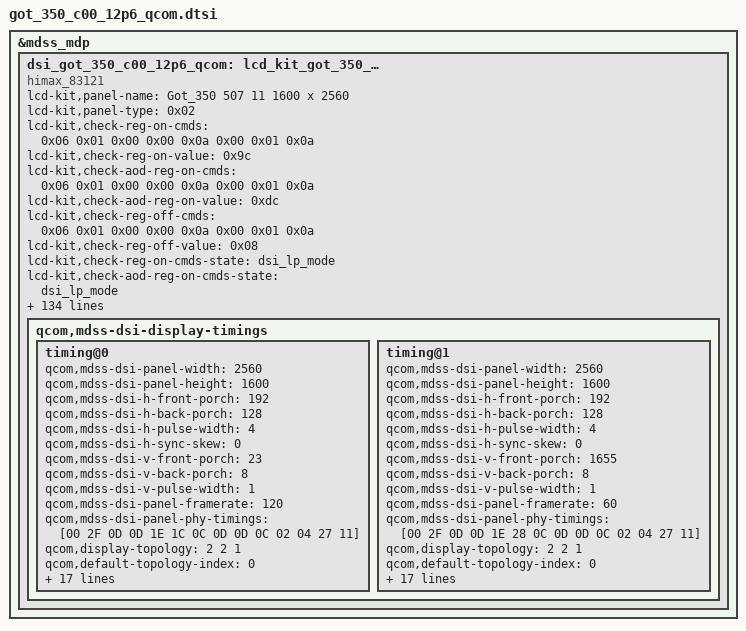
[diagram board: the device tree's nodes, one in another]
/* Copyright (c) 2013, The Linux Foundation. All rights reserved.
 *
 * This program is free software; you can redistribute it and/or modify
 * it under the terms of the GNU General Public License version 2 and
 * only version 2 as published by the Free Software Foundation.
 *
 * This program is distributed in the hope that it will be useful,
 * but WITHOUT ANY WARRANTY; without even the implied warranty of
 * MERCHANTABILITY or FITNESS FOR A PARTICULAR PURPOSE.  See the
 * GNU General Public License for more details.
 */

/*-------------------------------------------------------------------------
 * This file is autogenerated file using gcdb parser. Please do not edit it.
 * Update input XML file to add a new entry or update variable in this file
 * VERSION = 1.1
 *-----------------------------------------------------------------------*/
&mdss_mdp {
	dsi_got_350_c00_12p6_qcom: lcd_kit_got_350_c00_12p6_qcom {
		compatible = "himax_83121";
		lcd-kit,panel-name = "Got_350 507 11 1600 x 2560";
		lcd-kit,panel-type = <0x02>;
		lcd-kit,check-reg-on-cmds = <0x06 0x01 0x00 0x00 0x0a 0x00 0x01 0x0a>;
		lcd-kit,check-reg-on-value = <0x9c>;
		lcd-kit,check-aod-reg-on-cmds = <0x06 0x01 0x00 0x00 0x0a 0x00 0x01 0x0a>;
		lcd-kit,check-aod-reg-on-value = <0xdc>;
		lcd-kit,check-reg-off-cmds = <0x06 0x01 0x00 0x00 0x0a 0x00 0x01 0x0a>;
		lcd-kit,check-reg-off-value = <0x08>;
		lcd-kit,check-reg-on-cmds-state = "dsi_lp_mode";
		lcd-kit,check-aod-reg-on-cmds-state = "dsi_lp_mode";
		lcd-kit,check-reg-off-cmds-state = "dsi_lp_mode";
		lcd-kit,poweric-detect-support = <0>;
		lcd-kit,bl-after-frame = <0>;
		lcd-kit,cmd-async-support = <0>;
		lcd-kit,left-time-to-te-us = <25667>;
		lcd-kit,right-time-to-te-us = <26167>;
		lcd-kit,te-interval-time-us = <16667>;
		lcd-kit,check-reg-on-support = <0>;
		lcd-kit,check-reg-on-support-dsm-report = <0>;
		lcd-kit,check-aod-reg-on-support = <0>;
		lcd-kit,check-aod-reg-on-support-dsm-report = <0>;
		lcd-kit,check-reg-off-support = <0>;
		lcd-kit,check-reg-off-support-dsm-report = <0>;
		lcd-kit,vtc-line-no-reset = <1>;
		qcom,mdss-dsi-panel-type = "dsi_cmd_mode";
		qcom,mdss-dsi-panel-name = "himax_83121";
		qcom,mdss-pan-physical-width-dimension = <237>;
		qcom,mdss-pan-physical-height-dimension = <148>;
		qcom,dsi-ctrl-num = <0>;
		qcom,dsi-phy-num = <0>;
		qcom,panel-supply-entries = <&dsi_panel_pwr_supply>;
		qcom,mdss-dsi-virtual-channel-id = <0>;
		qcom,mdss-dsi-h-sync-pulse = <0>;
		qcom,mdss-dsi-bllp-eof-power-mode;
		qcom,mdss-dsi-bllp-power-mode;
		qcom,mdss-dsi-dma-schedule-line = <1>;
		qcom,mdss-dsi-bpp = <24>;
		qcom,mdss-dsi-color-order = "rgb_swap_rgb";
		qcom,mdss-dsi-underflow-color = <0xff>;
		qcom,mdss-dsi-border-color = <0>;
		qcom,mdss-dsi-traffic-mode = "burst_mode";
		qcom,mdss-dsi-lane-map = "lane_map_0123";
		qcom,mdss-dsi-lane-0-state;
		qcom,mdss-dsi-lane-1-state;
		qcom,mdss-dsi-lane-2-state;
		qcom,mdss-dsi-lane-3-state;
		qcom,mdss-dsi-mdp-trigger = "none";
		qcom,mdss-dsi-dma-trigger = "trigger_sw";
		qcom,mdss-dsi-te-pin-select = <1>;
		qcom,mdss-dsi-wr-mem-start = <0x2c>;
		qcom,mdss-dsi-wr-mem-continue = <0x3c>;
		qcom,mdss-dsi-te-dcs-command = <1>;
		qcom,mdss-dsi-te-check-enable;
		qcom,mdss-dsi-te-using-te-pin;
		qcom,mdss-dsi-t-clk-post = <0>;
		qcom,mdss-dsi-t-clk-pre = <0>;
		qcom,dsi-select-clocks = "mux_byte_clk0", "mux_pixel_clk0";
		qcom,mdss-dsi-stream = <0>;
		lcd-kit,check-thread-support = <0>;
		lcd-kit,check-time-period = <5000>;
		lcd-kit,check-fold-support = <0>;
		lcd-kit,fold-low-power-support = <0>;
		lcd-kit,fold-height = <0>;
		lcd-kit,unfold-height = <0>;
		lcd-kit,power-support = <0>;
		lcd-kit,three-stage-poweron = <0>;
		qcom,apaod-lp2-need-sendcmd;
		lcd-kit,fold-lp-time = <0>;
		lcd-kit,fold-nolp-time = <0>;
		qcom,sublinks-count = <2>;
		qcom,lanes-per-sublink = <2>;
		qcom,mdss-dsi-panel-hdr-color-primaries = <14500 15500 32000 17000 15500 30000 8000 3000>;
		qcom,mdss-dsi-panel-peak-brightness = <4200000>;
		qcom,mdss-dsi-panel-blackness-level = <3230>;
		qcom,dynamic-mode-switch-enabled;
		qcom,dynamic-mode-switch-type = "dynamic-resolution-switch-immediate";
		qcom,mdss-dsi-bl-pmic-control-type = "bl_ctrl_dcs";
		qcom,bl-pmic-pwm-period-usecs = <100>;
		qcom,mdss-dsi-bl-min-level = <1>;
		qcom,mdss-dsi-bl-max-level = <4095>;
		qcom,esd-check-enabled;
		qcom,tp-esd-gpio-event;
		qcom,esd-gpio-detect-support;
		qcom,esd-only-gpio-detect;
		qcom,esd-gpio-detect-num0 = <24>;
		qcom,esd-gpio-normal-value0 = <0>;
		qcom,mdss-dsi-panel-status-command = [14 01 00 00 00 00 01 0A];
		qcom,mdss-dsi-panel-status-command-state = "dsi_lp_mode";
		qcom,mdss-dsi-panel-status-check-mode = "reg_read";
		qcom,mdss-dsi-panel-status-read-length = <4>;
		qcom,mdss-dsi-panel-status-value = <0x03 0x90 0x00 0x00>;
		lcd-kit,power-on-stage = <2 1 0
				5 0 10
				5 1 0
				7 1 50>;
		lcd-kit,lp-on-stage = <6 1 0
				8 1 0>;
		lcd-kit,lp-off-stage = <7 0 0
				8 0 1>;
		lcd-kit,power-off-stage = <6 0 20
				5 0 2
				2 0 110>;
		lcd-kit,only-power-off-stage = <0 0 0>;
		lcd-kit,pt-support = <0>;
		lcd-kit,panel-on-always-reset = <0>;
		lcd-kit,lcd-iovcc = <2 154 0>;
		lcd-kit,lcd-reset = <2 12 0>;
		lcd-kit,lcd-iovcc-name = "vddio";
		lcd-kit,project-id-support = <0>;
		lcd-kit,default-project-id = "G21579250";
		lcd-kit,sn-code-support = <1>;
		lcd-kit,oem-info-support = <1>;
		lcd-kit,oem-barcode-2d-support = <1>;
		lcd-kit,oem-barcode-2d-num-offset = <0>;
		lcd-kit,panel-getblmaxnit-type = <0>;
		lcd-kit,panel-blmaxnit-min-value = <400>;
		lcd-kit,inversion-support = <0>;
		lcd-kit,panel-gpio-offset = <1100>;
		lcd-kit,finger-unlock-state-support = <0>;
		lcd-kit,esd-reg-te-check = <0>;
		lcd-kit,panel-bl-max-nit = <1638>;
		lcd-kit,panel-bl-min = <35>;
		lcd-kit,panel-bl-max = <10000>;
		lcd-kit,panel-bl-def = <4095>;
		lcd-kit,check-reg-support = <0>;
		lcd-kit,thp-proximity-support = <0>;
		lcd-kit,proximity-reset-delay-min = <65>;
		lcd-kit,backlight-cmds = <0x39 0x01 0x00 0x00 0x00 0x00 0x03 0x51 0x00 0x00>;
		lcd-kit,backlight-cmds-state = "dsi_lp_mode";
		lcd-kit,backlight-order = <0>;
		lcd-kit,backlight-need-sync = <0>;
		lcd-kit,fps-support = <1>;
		lcd-kit,default-fps = <60>;
		lcd-kit,panel-support-fps-list = <120 60>;
		lcd-kit,fps-60-cmd = "vndservice call display.qservice 25 i32 0 i32 0";
		lcd-kit,fps-90-cmd = "vndservice call display.qservice 25 i32 2 i32 0";
		lcd-kit,fps-120-cmd = "vndservice call display.qservice 25 i32 1 i32 0";
		qcom,mdss-dsi-display-timings {
			timing@0 {
				qcom,mdss-dsi-panel-width = <2560>;
				qcom,mdss-dsi-panel-height = <1600>;
				qcom,mdss-dsi-h-front-porch = <192>;
				qcom,mdss-dsi-h-back-porch = <128>;
				qcom,mdss-dsi-h-pulse-width = <4>;
				qcom,mdss-dsi-h-sync-skew = <0>;
				qcom,mdss-dsi-v-front-porch = <23>;
				qcom,mdss-dsi-v-back-porch = <8>;
				qcom,mdss-dsi-v-pulse-width = <1>;
				qcom,mdss-dsi-panel-framerate = <120>;
				qcom,mdss-dsi-panel-phy-timings= [00 2F 0D 0D 1E 1C 0C
				0D 0D 0C 02 04 27 11];
				qcom,display-topology  = <2 2 1>;
				qcom,default-topology-index  = <0>;
				qcom,mdss-dsi-on-command = [29 01 00 00 01 00 09 80 90 00 81 E7 03 00 00 00
                          0A 01 00 00 0a 00 80
			  11 00 00 AB 30 80 06 40
			  0A 00 00 04 02 80 02 80
			  02 00 02 41 00 20 00 5C
			  00 08 00 0C 20 00 15 3C
			  18 00 10 E0 07 10 20 00
			  06 0F 0F 33 0E 1C 2A 38
		  	  46 54 62 69 70 77 79 7B
			  7D 7E 02 02 22 00 2A 40
			  2A BE 3A FC 3A FA 3A F8
			  3B 38 3B 78 3B B6 4B F6
			  4C 34 4C 74 5C 74 8C F4
			  00 00 00 00 00 00 00 00
			  00 00 00 00 00 00 00 00
			  00 00 00 00 00 00 00 00
			  00 00 00 00 00 00 00 00
			  00 00 00 00 00 00 00 00
			  05 01 00 00 05 00 01 00
                          29 01 00 00 01 00 09 80 A8 00 81 E7 00 00 00 00
                          29 01 00 00 01 00 09 80 3c 01 80 e7 0C 00 0A 90
                          29 01 00 00 01 00 09 80 40 01 80 e7 46 00 00 00
                          29 01 00 00 0A 00 09 80 44 01 80 e7 01 00 00 00
                          29 01 00 00 01 00 09 80 3c 01 80 e7 00 00 0A 90
                          29 01 00 00 01 00 09 80 40 01 80 e7 96 00 00 00
                          29 01 00 00 0A 00 09 80 44 01 80 e7 01 00 00 00
                          29 01 00 00 01 00 09 80 3c 01 80 e7 0C 00 0A 90
                          29 01 00 00 01 00 09 80 40 01 80 e7 01 00 00 00
                          29 01 00 00 0A 00 09 80 44 01 80 e7 01 00 00 00
                          29 01 00 00 01 00 09 80 3c 01 80 e7 00 00 0A 90
                          29 01 00 00 01 00 09 80 40 01 80 e7 86 00 00 00
                          29 01 00 00 0A 00 09 80 44 01 80 e7 01 00 00 00
                          29 01 00 00 01 00 09 80 3c 01 80 e7 0C 00 0A 90
                          29 01 00 00 01 00 09 80 40 01 80 e7 03 00 00 00
                          29 01 00 00 0A 00 09 80 44 01 80 e7 01 00 00 00
                          29 01 00 00 01 00 09 80 3c 01 80 e7 00 00 0A 90
                          29 01 00 00 01 00 09 80 40 01 80 e7 A6 00 00 00
                          29 01 00 00 0A 00 09 80 44 01 80 e7 01 00 00 00
                          29 01 00 00 01 00 09 80 78 01 80 e7 04 00 0A 90
                          29 01 00 00 01 00 09 80 00 01 A3 E7 13 00 00 00
                          29 01 00 00 01 00 09 80 B4 00 A3 E7 13 00 00 00
                          29 01 00 00 01 00 09 80 D4 00 A3 E7 13 00 00 00
                          29 01 00 00 01 00 09 80 94 00 A3 E7 13 00 00 00
                          05 01 00 00 96 00 01 11
                          29 01 00 00 01 00 09 80 44 00 80 E7 40 15 00 00
		          29 01 00 00 01 00 09 80 3C 01 80 E7 84 02 FC E7
			  29 01 00 00 01 00 09 80 40 01 80 E7 B0 16 8C 01
			  29 01 00 00 14 00 09 80 44 01 80 E7 01 00 00 00
			  29 01 00 00 01 00 09 80 3C 01 80 E7 88 02 FC E7
			  29 01 00 00 01 00 09 80 40 01 80 E7 01 00 00 00
			  29 01 00 00 14 00 09 80 44 01 80 E7 01 00 00 00
			  29 01 00 00 01 00 09 80 3C 01 80 E7 84 02 FC E7
			  29 01 00 00 01 00 09 80 40 01 80 E7 BC 10 8C 01
			  29 01 00 00 14 00 09 80 44 01 80 E7 01 00 00 00
			  29 01 00 00 01 00 09 80 3C 01 80 E7 88 02 FC E7
			  29 01 00 00 01 00 09 80 40 01 80 E7 01 00 00 00
			  29 01 00 00 14 00 09 80 44 01 80 E7 01 00 00 00
                          29 01 00 00 01 00 09 80 3C 01 80 E7 84 02 FC E7
                          29 01 00 00 01 00 09 80 40 01 80 E7 B0 08 8C 01
                          29 01 00 00 0A 00 09 80 44 01 80 E7 01 00 00 00
                          29 01 00 00 01 00 09 80 3C 01 80 E7 88 02 FC E7
                          29 01 00 00 01 00 09 80 40 01 80 E7 01 00 00 00
                          29 01 00 00 0A 00 09 80 44 01 80 E7 01 00 00 00
                          29 01 00 00 01 00 09 80 3C 01 80 E7 84 02 FC E7
                          29 01 00 00 01 00 09 80 40 01 80 E7 B5 3D 8C 01
                          29 01 00 00 0A 00 09 80 44 01 80 E7 01 00 00 00
                          29 01 00 00 01 00 09 80 3C 01 80 E7 88 02 FC E7
                          29 01 00 00 01 00 09 80 40 01 80 E7 01 00 00 00
                          29 01 00 00 0A 00 09 80 44 01 80 E7 01 00 00 00
                          05 01 00 00 00 00 01 29
                          29 01 00 00 0A 00 09 80 40 00 80 E7 7E 00 00 00
                          29 01 00 00 01 00 09 80 4C 00 80 E7 00 00 00 00
                          29 01 00 00 0F 00 09 80 58 00 80 E7 04 00 00 00
                          29 01 00 00 01 00 09 80 24 00 80 E7 7E 84 FB 7F
                          29 01 00 00 01 00 09 80 00 00 90 E7 00 0A 40 06
                          29 01 00 00 01 00 09 80 04 00 90 E7 07 00 00 00
                          29 01 00 00 01 00 09 80 08 00 90 E7 02 00 00 00
                          29 01 00 00 01 00 09 80 0C 00 90 E7 28 00 03 00
                          29 01 00 00 01 00 09 80 10 00 90 E7 33 06 06 00
                          29 01 00 00 01 00 09 80 14 00 90 E7 00 00 00 00
                          29 01 00 00 01 00 09 80 18 00 90 E7 00 00 00 00
                          29 01 00 00 01 00 09 80 1C 00 90 E7 00 00 00 00
                          29 01 00 00 01 00 09 80 20 00 90 E7 00 00 00 1C
                          29 01 00 00 01 00 09 80 24 00 90 E7 01 00 00 24
                          29 01 00 00 01 00 09 80 28 00 90 E7 00 00 00 00
                          29 01 00 00 01 00 09 80 2C 00 90 E7 00 00 00 0A
                          29 01 00 00 01 00 09 80 30 00 90 E7 01 00 00 38
                          29 01 00 00 01 00 09 80 34 00 90 E7 00 00 00 00
                          29 01 00 00 01 00 09 80 38 00 90 E7 00 00 00 0A
                          29 01 00 00 01 00 09 80 3C 00 90 E7 01 00 00 38
                          29 01 00 00 01 00 09 80 40 00 90 E7 00 00 00 00];
				qcom,mdss-dsi-on-command-state = "dsi_lp_mode";
				qcom,mdss-dsi-off-command = [05 01 00 00 0a 00 02 28 00
                        05 01 00 00 78 00 02 10 00];
				qcom,mdss-dsi-off-command-state = "dsi_lp_mode";
				qcom,compression-mode = "dsc";
				qcom,mdss-dsc-slice-height = <4>;
				qcom,mdss-dsc-slice-width = <640>;
				qcom,mdss-dsc-slice-per-pkt = <1>;
				qcom,mdss-dsc-bit-per-component = <10>;
				qcom,mdss-dsc-bit-per-pixel = <8>;
				qcom,mdss-dsc-block-prediction-enable;
				qcom,mdss-dsi-timing-switch-command = [29 01 00 00 01 00 09 80 4C 00 80 E7 00 00 00 00
                                    29 01 00 00 0F 00 09 80 58 00 80 E7 04 00 00 00];
				qcom,mdss-dsi-timing-switch-command-state = "dsi_lp_mode";
			};
			timing@1 {
				qcom,mdss-dsi-panel-width = <2560>;
				qcom,mdss-dsi-panel-height = <1600>;
				qcom,mdss-dsi-h-front-porch = <192>;
				qcom,mdss-dsi-h-back-porch = <128>;
				qcom,mdss-dsi-h-pulse-width = <4>;
				qcom,mdss-dsi-h-sync-skew = <0>;
				qcom,mdss-dsi-v-front-porch = <1655>;
				qcom,mdss-dsi-v-back-porch = <8>;
				qcom,mdss-dsi-v-pulse-width = <1>;
				qcom,mdss-dsi-panel-framerate = <60>;
				qcom,mdss-dsi-panel-phy-timings= [00 2F 0D 0D 1E 28 0C
                        0D 0D 0C 02 04 27 11];
				qcom,display-topology  = <2 2 1>;
				qcom,default-topology-index  = <0>;
				qcom,mdss-dsi-on-command = [29 01 00 00 01 00 09 80 90 00 81 E7 03 00 00 00
                          0A 01 00 00 0a 00 80
                          11 00 00 AB 30 80 06 40
                          0A 00 00 04 02 80 02 80
                          02 00 02 41 00 20 00 5C
                          00 08 00 0C 20 00 15 3C
                          18 00 10 E0 07 10 20 00
                          06 0F 0F 33 0E 1C 2A 38
                          46 54 62 69 70 77 79 7B
                          7D 7E 02 02 22 00 2A 40
                          2A BE 3A FC 3A FA 3A F8
                          3B 38 3B 78 3B B6 4B F6
                          4C 34 4C 74 5C 74 8C F4
                          00 00 00 00 00 00 00 00
                          00 00 00 00 00 00 00 00
                          00 00 00 00 00 00 00 00
                          00 00 00 00 00 00 00 00
                          00 00 00 00 00 00 00 00
                          05 01 00 00 05 00 01 00
                          29 01 00 00 01 00 09 80 A8 00 81 E7 00 00 00 00
                          29 01 00 00 01 00 09 80 3c 01 80 e7 0C 00 0A 90
                          29 01 00 00 01 00 09 80 40 01 80 e7 46 00 00 00
                          29 01 00 00 0A 00 09 80 44 01 80 e7 01 00 00 00
                          29 01 00 00 01 00 09 80 3c 01 80 e7 00 00 0A 90
                          29 01 00 00 01 00 09 80 40 01 80 e7 96 00 00 00
                          29 01 00 00 0A 00 09 80 44 01 80 e7 01 00 00 00
                          29 01 00 00 01 00 09 80 3c 01 80 e7 0C 00 0A 90
                          29 01 00 00 01 00 09 80 40 01 80 e7 01 00 00 00
                          29 01 00 00 0A 00 09 80 44 01 80 e7 01 00 00 00
                          29 01 00 00 01 00 09 80 3c 01 80 e7 00 00 0A 90
                          29 01 00 00 01 00 09 80 40 01 80 e7 86 00 00 00
                          29 01 00 00 0A 00 09 80 44 01 80 e7 01 00 00 00
                          29 01 00 00 01 00 09 80 3c 01 80 e7 0C 00 0A 90
                          29 01 00 00 01 00 09 80 40 01 80 e7 03 00 00 00
                          29 01 00 00 0A 00 09 80 44 01 80 e7 01 00 00 00
                          29 01 00 00 01 00 09 80 3c 01 80 e7 00 00 0A 90
                          29 01 00 00 01 00 09 80 40 01 80 e7 A6 00 00 00
                          29 01 00 00 0A 00 09 80 44 01 80 e7 01 00 00 00
                          29 01 00 00 01 00 09 80 78 01 80 e7 04 00 0A 90
                          29 01 00 00 01 00 09 80 00 01 A3 E7 13 00 00 00
                          29 01 00 00 01 00 09 80 B4 00 A3 E7 13 00 00 00
                          29 01 00 00 01 00 09 80 D4 00 A3 E7 13 00 00 00
                          29 01 00 00 01 00 09 80 94 00 A3 E7 13 00 00 00
                          05 01 00 00 96 00 01 11
                          29 01 00 00 01 00 09 80 44 00 80 E7 40 15 00 00
			  29 01 00 00 01 00 09 80 3C 01 80 E7 84 02 FC E7
			  29 01 00 00 01 00 09 80 40 01 80 E7 B0 16 8C 01
			  29 01 00 00 14 00 09 80 44 01 80 E7 01 00 00 00
			  29 01 00 00 01 00 09 80 3C 01 80 E7 88 02 FC E7
			  29 01 00 00 01 00 09 80 40 01 80 E7 01 00 00 00
			  29 01 00 00 14 00 09 80 44 01 80 E7 01 00 00 00
			  29 01 00 00 01 00 09 80 3C 01 80 E7 84 02 FC E7
			  29 01 00 00 01 00 09 80 40 01 80 E7 BC 10 8C 01
			  29 01 00 00 14 00 09 80 44 01 80 E7 01 00 00 00
			  29 01 00 00 01 00 09 80 3C 01 80 E7 88 02 FC E7
			  29 01 00 00 01 00 09 80 40 01 80 E7 01 00 00 00
			  29 01 00 00 14 00 09 80 44 01 80 E7 01 00 00 00
                          29 01 00 00 01 00 09 80 3C 01 80 E7 84 02 FC E7
                          29 01 00 00 01 00 09 80 40 01 80 E7 B0 08 8C 01
                          29 01 00 00 0A 00 09 80 44 01 80 E7 01 00 00 00
                          29 01 00 00 01 00 09 80 3C 01 80 E7 88 02 FC E7
                          29 01 00 00 01 00 09 80 40 01 80 E7 01 00 00 00
                          29 01 00 00 0A 00 09 80 44 01 80 E7 01 00 00 00
                          29 01 00 00 01 00 09 80 3C 01 80 E7 84 02 FC E7
                          29 01 00 00 01 00 09 80 40 01 80 E7 B5 3D 8C 01
                          29 01 00 00 0A 00 09 80 44 01 80 E7 01 00 00 00
                          29 01 00 00 01 00 09 80 3C 01 80 E7 88 02 FC E7
                          29 01 00 00 01 00 09 80 40 01 80 E7 01 00 00 00
                          29 01 00 00 0A 00 09 80 44 01 80 E7 01 00 00 00
                          05 01 00 00 00 00 01 29
                          29 01 00 00 0A 00 09 80 40 00 80 E7 7E 00 00 00
                          29 01 00 00 01 00 09 80 4C 00 80 E7 01 00 00 00
                          29 01 00 00 0F 00 09 80 58 00 80 E7 04 00 00 00
                          29 01 00 00 01 00 09 80 24 00 80 E7 7E 84 FB 7F
                          29 01 00 00 01 00 09 80 00 00 90 E7 00 0A 40 06
                          29 01 00 00 01 00 09 80 04 00 90 E7 07 00 00 00
                          29 01 00 00 01 00 09 80 08 00 90 E7 02 00 00 00
                          29 01 00 00 01 00 09 80 0C 00 90 E7 28 00 03 00
                          29 01 00 00 01 00 09 80 10 00 90 E7 33 06 06 00
                          29 01 00 00 01 00 09 80 14 00 90 E7 00 00 00 00
                          29 01 00 00 01 00 09 80 18 00 90 E7 00 00 00 00
                          29 01 00 00 01 00 09 80 1C 00 90 E7 00 00 00 00
                          29 01 00 00 01 00 09 80 20 00 90 E7 00 00 00 1C
                          29 01 00 00 01 00 09 80 24 00 90 E7 01 00 00 24
                          29 01 00 00 01 00 09 80 28 00 90 E7 00 00 00 00
                          29 01 00 00 01 00 09 80 2C 00 90 E7 00 00 00 0A
                          29 01 00 00 01 00 09 80 30 00 90 E7 01 00 00 38
                          29 01 00 00 01 00 09 80 34 00 90 E7 00 00 00 00
                          29 01 00 00 01 00 09 80 38 00 90 E7 00 00 00 0A
                          29 01 00 00 01 00 09 80 3C 00 90 E7 01 00 00 38
                          29 01 00 00 01 00 09 80 40 00 90 E7 00 00 00 00];
				qcom,mdss-dsi-on-command-state = "dsi_lp_mode";
				qcom,mdss-dsi-off-command = [05 01 00 00 0a 00 02 28 00
                        05 01 00 00 78 00 02 10 00];
				qcom,mdss-dsi-off-command-state = "dsi_lp_mode";
				qcom,compression-mode = "dsc";
				qcom,mdss-dsc-slice-height = <4>;
				qcom,mdss-dsc-slice-width = <640>;
				qcom,mdss-dsc-slice-per-pkt = <1>;
				qcom,mdss-dsc-bit-per-component = <10>;
				qcom,mdss-dsc-bit-per-pixel = <8>;
				qcom,mdss-dsc-block-prediction-enable;
				qcom,mdss-dsi-timing-switch-command = [29 01 00 00 01 00 09 80 4C 00 80 E7 01 00 00 00
                                    29 01 00 00 1F 00 09 80 58 00 80 E7 04 00 00 00];
				qcom,mdss-dsi-timing-switch-command-state = "dsi_lp_mode";
			};
		};
    };
};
